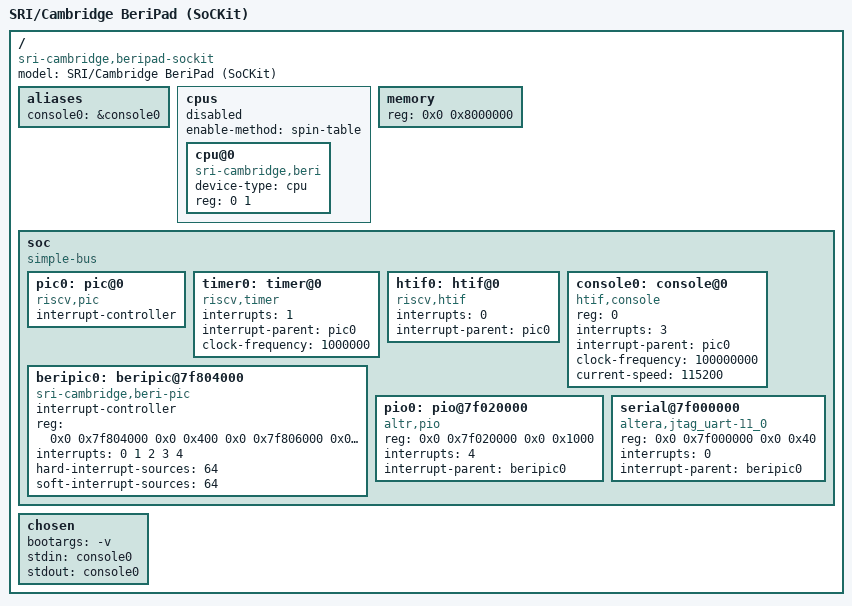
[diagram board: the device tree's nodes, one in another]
/*-
 * Copyright (c) 2015 Ruslan Bukin <br@bsdpad.com>
 * All rights reserved.
 *
 * Redistribution and use in source and binary forms, with or without
 * modification, are permitted provided that the following conditions
 * are met:
 * 1. Redistributions of source code must retain the above copyright
 *    notice, this list of conditions and the following disclaimer.
 * 2. Redistributions in binary form must reproduce the above copyright
 *    notice, this list of conditions and the following disclaimer in the
 *    documentation and/or other materials provided with the distribution.
 *
 * THIS SOFTWARE IS PROVIDED BY THE AUTHOR AND CONTRIBUTORS ``AS IS'' AND
 * ANY EXPRESS OR IMPLIED WARRANTIES, INCLUDING, BUT NOT LIMITED TO, THE
 * IMPLIED WARRANTIES OF MERCHANTABILITY AND FITNESS FOR A PARTICULAR PURPOSE
 * ARE DISCLAIMED.  IN NO EVENT SHALL THE AUTHOR OR CONTRIBUTORS BE LIABLE
 * FOR ANY DIRECT, INDIRECT, INCIDENTAL, SPECIAL, EXEMPLARY, OR CONSEQUENTIAL
 * DAMAGES (INCLUDING, BUT NOT LIMITED TO, PROCUREMENT OF SUBSTITUTE GOODS
 * OR SERVICES; LOSS OF USE, DATA, OR PROFITS; OR BUSINESS INTERRUPTION)
 * HOWEVER CAUSED AND ON ANY THEORY OF LIABILITY, WHETHER IN CONTRACT, STRICT
 * LIABILITY, OR TORT (INCLUDING NEGLIGENCE OR OTHERWISE) ARISING IN ANY WAY
 * OUT OF THE USE OF THIS SOFTWARE, EVEN IF ADVISED OF THE POSSIBILITY OF
 * SUCH DAMAGE.
 *
 * $FreeBSD$
 */

/dts-v1/;

/*
 * Device names here have been largely made up on the spot, especially for the
 * "compatible" strings, and might want to be revised.
 */

/ {
	model = "SRI/Cambridge BeriPad (SoCKit)";
	compatible = "sri-cambridge,beripad-sockit";
	#address-cells = <1>;
	#size-cells = <1>;
	#interrupt-cells = <1>;

	aliases {
		console0 = &console0;
	};

	cpus {
		#address-cells = <1>;
		#size-cells = <1>;

		/*
		 * Secondary CPUs all start disabled and use the
		 * spin-table enable method.  cpu-release-addr must be
		 * specified for each cpu other than cpu@0.  Values of
		 * cpu-release-addr grow down from 0x100000 (kernel).
		 */
		status = "disabled";
		enable-method = "spin-table";

		cpu@0 {
			device-type = "cpu";
			compatible = "sri-cambridge,beri";

			reg = <0 1>;
			status = "okay";
		};
	};

	memory {
		device_type = "memory";
		reg = <0x0 0x8000000>; /* 128MB at 0x0 */
	};

	soc {
		#address-cells = <2>;
		#size-cells = <2>;
		#interrupt-cells = <1>;

		compatible = "simple-bus";
		ranges;

		pic0: pic@0 {
			compatible = "riscv,pic";
			interrupt-controller;
		};

		timer0: timer@0 {
			compatible = "riscv,timer";
			interrupts = < 1 >;
			interrupt-parent = < &pic0 >;
			clock-frequency = < 1000000 >;
		};

		htif0: htif@0 {
			compatible = "riscv,htif";
			interrupts = < 0 >;
			interrupt-parent = < &pic0 >;
		};

		console0: console@0 {
			compatible = "htif,console";
			status = "okay";
			reg = < 0 >;
			interrupts = < 3 >;
			interrupt-parent = < &pic0 >;
			clock-frequency = < 100000000 >;
			current-speed = <115200>;
		};

		beripic0: beripic@7f804000 {
			compatible = "sri-cambridge,beri-pic";
			interrupt-controller;
			#address-cells = <0>;
			#interrupt-cells = <1>;
			reg = <0x0 0x7f804000 0x0 0x400
			       0x0 0x7f806000 0x0 0x10
			       0x0 0x7f806080 0x0 0x10
			       0x0 0x7f806100 0x0 0x10>;
			interrupts = <0 1 2 3 4>;
			hard-interrupt-sources = <64>;
			soft-interrupt-sources = <64>;
		};

		pio0: pio@7f020000 {
			compatible = "altr,pio";
			reg = <0x0 0x7f020000 0x0 0x1000>; /* send */
			interrupts = <4>; /* not used */
			interrupt-parent = <&beripic0>;
		};

		serial@7f000000 {
			compatible = "altera,jtag_uart-11_0";
			reg = <0x0 0x7f000000 0x0 0x40>;
			interrupts = <0>;
			interrupt-parent = <&beripic0>;
		};
	};

	chosen {
		bootargs = "-v";
		stdin = "console0";
		stdout = "console0";
	};
};
